# RSL15 register map
Vendor: ONSemiconductor; Series: RSL15 Series; File version: 1.0
CPU: CM33 r0p4, little endian, MPU, FPU, 3 interrupt priority bits
Registers are 32-bit, read-write, reset 0x0 unless marked. A register's access mark holds for its fields unless they carry their own. Offsets are from the block's base; [hi:lo] are bit positions; {n}, {i} and the like mark numbered series; <NAME> marks a mode.

## SENSOR — Sensor Interface
Base 0x40001D00
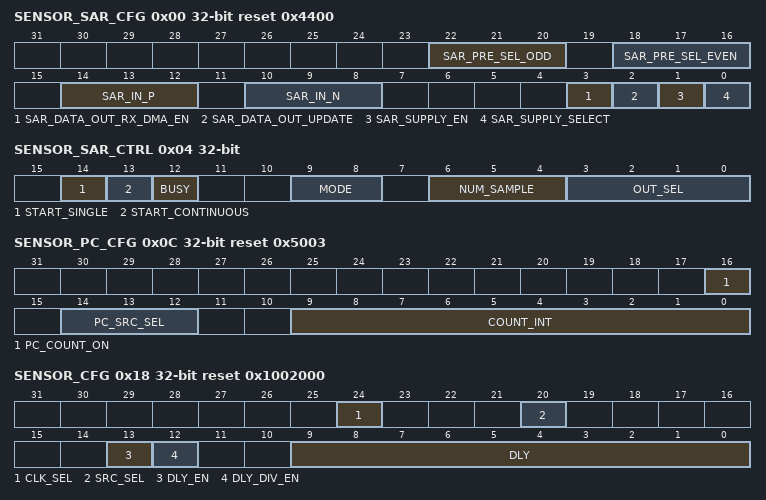
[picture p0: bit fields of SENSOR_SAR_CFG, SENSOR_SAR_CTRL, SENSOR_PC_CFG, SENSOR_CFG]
0x00 SENSOR_SAR_CFG reset 0x4400 — SAR configuration
  [22:20] SAR_PRE_SEL_ODD — Pre-selection of odd GPIOs
    0=SAR_PRE_SEL_GPIO_1 (Select GPIO[1] for "pre_sel_odd"); 1=SAR_PRE_SEL_GPIO_3 (Select GPIO[3] for "pre_sel_odd"); 2=SAR_PRE_SEL_GPIO_5 (Select GPIO[5] for "pre_sel_odd"); 3=SAR_PRE_SEL_GPIO_7 (Select GPIO[7] for "pre_sel_odd"); 4=SAR_PRE_SEL_GPIO_9 (Select GPIO[9] for "pre_sel_odd"); 5=SAR_PRE_SEL_GPIO_11 (Select GPIO[11] for "pre_sel_odd"); 6=SAR_PRE_SEL_GPIO_13 (Select GPIO[13] for "pre_sel_odd"); 7=SAR_PRE_SEL_GPIO_15 (Select GPIO[15] for "pre_sel_odd")
  [18:16] SAR_PRE_SEL_EVEN — Pre-selection of even GPIOs
    0=SAR_PRE_SEL_GPIO_0 (Select GPIO[0] for "pre_sel_even"); 1=SAR_PRE_SEL_GPIO_2 (Select GPIO[2] for "pre_sel_even"); 2=SAR_PRE_SEL_GPIO_4 (Select GPIO[4] for "pre_sel_even"); 3=SAR_PRE_SEL_GPIO_6 (Select GPIO[6] for "pre_sel_even"); 4=SAR_PRE_SEL_GPIO_8 (Select GPIO[8] for "pre_sel_even"); 5=SAR_PRE_SEL_GPIO_10 (Select GPIO[10] for "pre_sel_even"); 6=SAR_PRE_SEL_GPIO_12 (Select GPIO[12] for "pre_sel_even"); 7=SAR_PRE_SEL_GPIO_14 (Select GPIO[14] for "pre_sel_even")
  [14:12] SAR_IN_P — Defines the positive input signal
    0=SAR_IN_P_SRC_PRE_SEL_EVEN (Select "pre_sel_even" as source); 1=SAR_IN_P_SRC_PRE_SEL_ODD (Select "pre_sel_odd" as source); 2=SAR_IN_P_SRC_SDAC (Select SDAC as source); 3=SAR_IN_P_SRC_SAR_SUPPLY (Select SAR-ADC supply as source); 4=SAR_IN_P_SRC_SAR_SUPPLY_DIV2 (Select SAR-ADC supply divided by 2 as source)
  [10:8] SAR_IN_N — Defines the negative input signal
    0=SAR_IN_N_SRC_PRE_SEL_EVEN (Select "pre_sel_even" as source); 1=SAR_IN_N_SRC_PRE_SEL_ODD (Select "pre_sel_odd" as source); 2=SAR_IN_N_SRC_SDAC (Select SDAC as source); 3=SAR_IN_N_SRC_VSSA (Select VSSA as source); 4=SAR_IN_N_SRC_SAR_SUPPLY_DIV2 (Select SAR-ADC supply divided by 2 as source)
  [3] SAR_DATA_OUT_RX_DMA_EN — Enable / disable the DMA trigger when SAR data available
    0=SAR_DATA_OUT_RX_DMA_DISABLED (No RX DMA triggered); 1=SAR_DATA_OUT_RX_DMA_ENABLED (RX DMA triggered when SAR data available)
  [2] SAR_DATA_OUT_UPDATE — Enable / disable the SAR data update
    0=SAR_DATA_OUT_UPDATE_AUTO (The SAR data buffer updated at the end of a conversion); 1=SAR_DATA_OUT_UPDATE_ENABLE (The SAR data buffer updated at each clock cycle)
  [1] SAR_SUPPLY_EN — Enable / disable the SAR supply
    0=SAR_SUPPLY_AUTO (The SAR supply is in auto mode); 1=SAR_SUPPLY_ENABLE (The SAR supply is enabled.)
  [0] SAR_SUPPLY_SELECT — SAR supply selection
    0=SAR_SUPPLY_BY_VBAT (SAR ADC supplied by VBAT); 1=SAR_SUPPLY_BY_GPIO9 (SAR ADC supplied by GPIO9)
0x04 SENSOR_SAR_CTRL (reset mask 0x337F) — SAR control register
  [14] START_SINGLE wo — Start single conversion command
    1=SAR_START_SINGLE (Start single conversion)
  [13] START_CONTINUOUS — Start continuous conversions command
    1=SAR_START_CONTINUOUS (Start continuous conversions); 0=SAR_STOP_CONTINUOUS (Stop continuous conversions)
  [12] BUSY ro — Conversion in progess flag
    0=SAR_IDLE (Idle or conversion done); 1=SAR_BUSY (Conversion in progress)
  [9:8] MODE — Conversion mode selection
    0=SAR_CONV_12BIT (Convert 12 bits); 1=SAR_CONV_14BIT (Convert 14 bits); 2=SAR_CAL_WEIGHT (Gain compensation (calibration)); 3=SAR_AUTO_ZERO (Offset compensation (calibration))
  [6:4] NUM_SAMPLE — Defines the number of clk cycles for data sampling
    0=SAR_NSAMPLING_CYCLE_1 (1 cycle); {v}=SAR_NSAMPLING_CYCLE_{v+1} ({v+1} cycles) (v=1..7)
  [3:0] OUT_SEL — Output selection (undefined values return 0)
    0=SAR_SEL_GATED_SIGNED_COMPENSATED (Gated 2's complement offset compensated output); 1=SAR_SEL_GATED_SIGNED (Gated 2's complement output); 2=SAR_SEL_GATED_UNSIGNED_COMPENSATED (Gated unsigned offset compensated output); 3=SAR_SEL_GATED_UNSIGNED (Gated unsigned output); 4=SAR_SEL_ACCUMULATOR (Accumulator output (test purposes)); 5=SAR_SEL_DAC (DAC signal (to analog) selection (test purposes)); 6=SAR_SEL_COMP_CNT (Comparator output (from analog) and counters selection (test purposes)); 8=SAR_SEL_OFFSET (Select offset compensation register (calibration)); {v}=SAR_SEL_WEIGHT_BIT{v} (Select bit {v} weight gain compensation register (calibration)) (v=9..14)
0x08 SENSOR_SAR_DATA ro — SAR data out
  [15:0] SAR_OUT — 15 bit SAR conversion result (signed)
0x0C SENSOR_PC_CFG reset 0x5003 — Sensor Pulse Counter Configuration
  [16] PC_COUNT_ON — Pulse counter count on rising edge or high state
    0=PC_COUNT_ON_HIGH_LEVEL (Count on high level); 1=PC_COUNT_ON_RISING_EDGE (Count on rising edge)
  [14:12] PC_SRC_SEL — Pulse count source selection
    {v}=PC_SRC_GPIO_{v} (Select GPIO[{v}] as source) (v=0..3); 4=PC_SRC_CONST_LOW (Select constant low as source); 5=PC_SRC_CONST_HIGH (Select constant high as source)
  [9:0] COUNT_INT — Duration of count state
    {v}=Number of SENSOR_CLK periods for "Count Sample State": {v+1} (v=0..3); 255=Number of SENSOR_CLK periods for "Count Sample State": 256; 0x3FE=Number of SENSOR_CLK periods for "Count Sample State": 1023
0x10 SENSOR_PC_COUNT ro — Sensor Pulse Counter Current Value
  [9:0] VALUE — Sensor pulse counter current value
0x14 SENSOR_TIMER_COUNT ro — Sensor Configuration
  [9:0] VALUE — Sensor timer counter current value
0x18 SENSOR_CFG reset 0x1002000 — Sensor Configuration
  [24] CLK_SEL — Clock source selection
    0=SENSOR_CLK_STANDBY (Standby clock is used as sensor clock); 1=SENSOR_CLK_SYSCLK_DIV (Divided SYSCLK is used as sensor clock)
  [20] SRC_SEL — Sample source selection
    0=SAR_ADC_SELECTED (SAR ADC sample selected); 1=PC_SELECTED (Pulse Counter sample selected)
  [13] DLY_EN — Delay state enable
    0=DLY_NOT_USED (Delay state is not used); 1=DLY_USED (Delay state is used)
  [12] DLY_DIV_EN — Delay divider selection
    0=DLY_DIV_DISABLED (Delay runs at sensor clock); 1=DLY_DIV_ENABLED (Delay runs at sensor clock divided by 32)
  [9:0] DLY — Absolute Value of main counter to trigger the change of delay state
    0=Number of SENSOR_CLK periods for "Delay": 1; 1=Number of SENSOR_CLK periods for "Delay": 2; 255=Number of SENSOR_CLK periods for "Delay": 256; 0x3FF=Number of SENSOR_CLK periods for "Delay": 1024
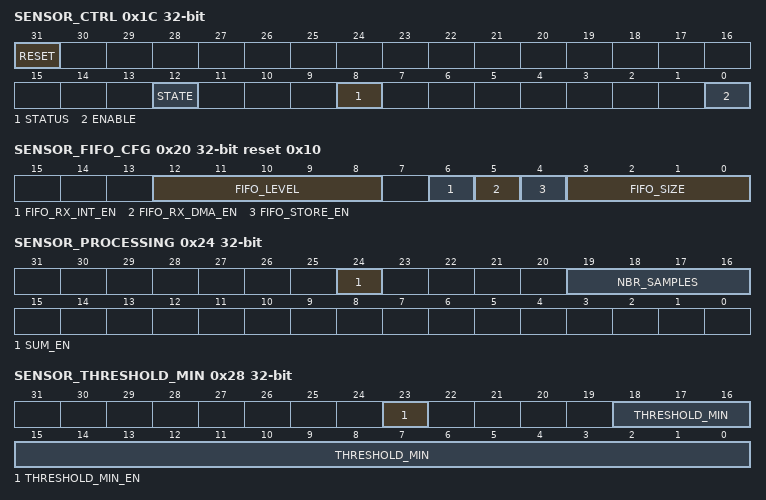
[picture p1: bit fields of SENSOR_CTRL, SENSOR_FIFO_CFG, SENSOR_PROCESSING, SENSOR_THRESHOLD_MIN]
0x1C SENSOR_CTRL (reset mask 0x1101) — Sensor Control
  [31] RESET wo — Reset the Sensor interface (SAR and Pulse Counter)
    1=SENSOR_RESET (The sensor timer counter, the SAR-ADC analog, the sensor enable and the pulse counter are reset.)
  [12] STATE ro — Sensor state
    0=DELAY_STATUS (Sensor in delay state or in idle state); 1=COUNT_STATUS (Sensor in count state)
  [8] STATUS ro — Sensor status
    0=SENSOR_IDLE (Sensor state machine in idle mode); 1=SENSOR_RUNNING (Sensor state machine in active mode)
  [0] ENABLE — Sensor
    0=SENSOR_DISABLE (Sensor disables); 1=SENSOR_ENABLE (Sensor enables)
0x20 SENSOR_FIFO_CFG reset 0x10 — Sensor ADC data FIFO configuration
  [12:8] FIFO_LEVEL ro — Number of samples stored in FIFO
    0=SENSOR_FIFO_EMPTY (FIFO data level is 0); 16=SENSOR_FIFO_FULL (FIFO data level is 16)
  [6] FIFO_RX_INT_EN — Enable / disable the interrupt when FIFO is full
    0=FIFO_RX_INT_DISABLED (No RX interrupt); 1=FIFO_RX_INT_ENABLED (RX interrupt when FIFO is full)
  [5] FIFO_RX_DMA_EN — Enable / disable the DMA trigger when FIFIO is full
    0=FIFO_RX_DMA_DISABLED (No RX DMA triggered); 1=FIFO_RX_DMA_ENABLED (RX DMA triggered when FIFO is full)
  [4] FIFO_STORE_EN — Enable the storage of sample on the FIFO
    0=SENSOR_FIFO_STORE_DISABLED (Samples are not stored in the FIFO); 1=SENSOR_FIFO_STORE_ENABLED (Samples are stored in the FIFO)
  [3:0] FIFO_SIZE — Number of samples stored before waking up the core
    0=SENSOR_FIFO_SIZE1 (FIFO size 1; core wakes up after first sample arrives); {v}=SENSOR_FIFO_SIZE{v+1} (FIFO size {v+1}) (v=1..15)
0x24 SENSOR_PROCESSING — Sensor ADC wake-up threshold
  [24] SUM_EN — Summation enable
    0=SENSOR_SUMMATION_DISABLED (Summation is disabled); 1=SENSOR_SUMMATION_ENABLED (Summation is enabled)
  [19:16] NBR_SAMPLES — Number of samples used for wakeup in sensor detect mode
    0=SENSOR_NBR_SAMPLES_1 (1 sample used); 1=SENSOR_NBR_SAMPLES_2 (2 samples used); 15=SENSOR_NBR_SAMPLES_16 (16 samples used)
0x28 SENSOR_THRESHOLD_MIN — Sensor Threshold configuration
  [23] THRESHOLD_MIN_EN — Threshold min comparator is enabled.
    0=SENSOR_THRESHOLD_MIN_DISABLED (Threshold min comparator disables.); 1=SENSOR_THRESHOLD_MIN_ENABLED (Threshold min comparator enables.)
  [18:0] THRESHOLD_MIN — Absolute sensor data threshold min for wake-up
    0=SENSOR_THRESHOLD_MIN_0 (Increments counter if sample is <= 0x00000); 1=SENSOR_THRESHOLD_MIN_1 (Increments counter if sample is <= 0x00001); 0x3FFFF=SENSOR_THRESHOLD_MIN_32767 (Increments counter if sample is <= 0x3FFFF)
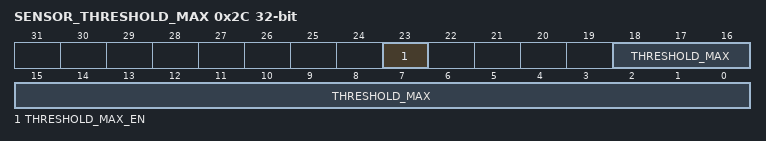
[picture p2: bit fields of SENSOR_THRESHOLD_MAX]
0x2C SENSOR_THRESHOLD_MAX — Sensor Threshold configuration
  [23] THRESHOLD_MAX_EN — Threshold max comparator is enabled
    0=SENSOR_THRESHOLD_MAX_DISABLED (Threshold max comparator disables.); 1=SENSOR_THRESHOLD_MAX_ENABLED (Threshold max comparator enables.)
  [18:0] THRESHOLD_MAX — Absolute sensor data threshold max for wake-up
    0=SENSOR_THRESHOLD_MAX_0 (Increments counter if sample is >= 0x00000); 1=SENSOR_THRESHOLD_MAX_1 (Increments counter if sample is >= 0x00001); 0x3FFFF=SENSOR_THRESHOLD_MAX_32767 (Increments counter if sample is >= 0x3FFFF)
{0x30+4i} SENSOR_FIFO_DATA[{i}] (i=0..15) ro — Sensor ADC output data FIFO
  [31:0] VALUE — Sensor FIFO output data (signed)
